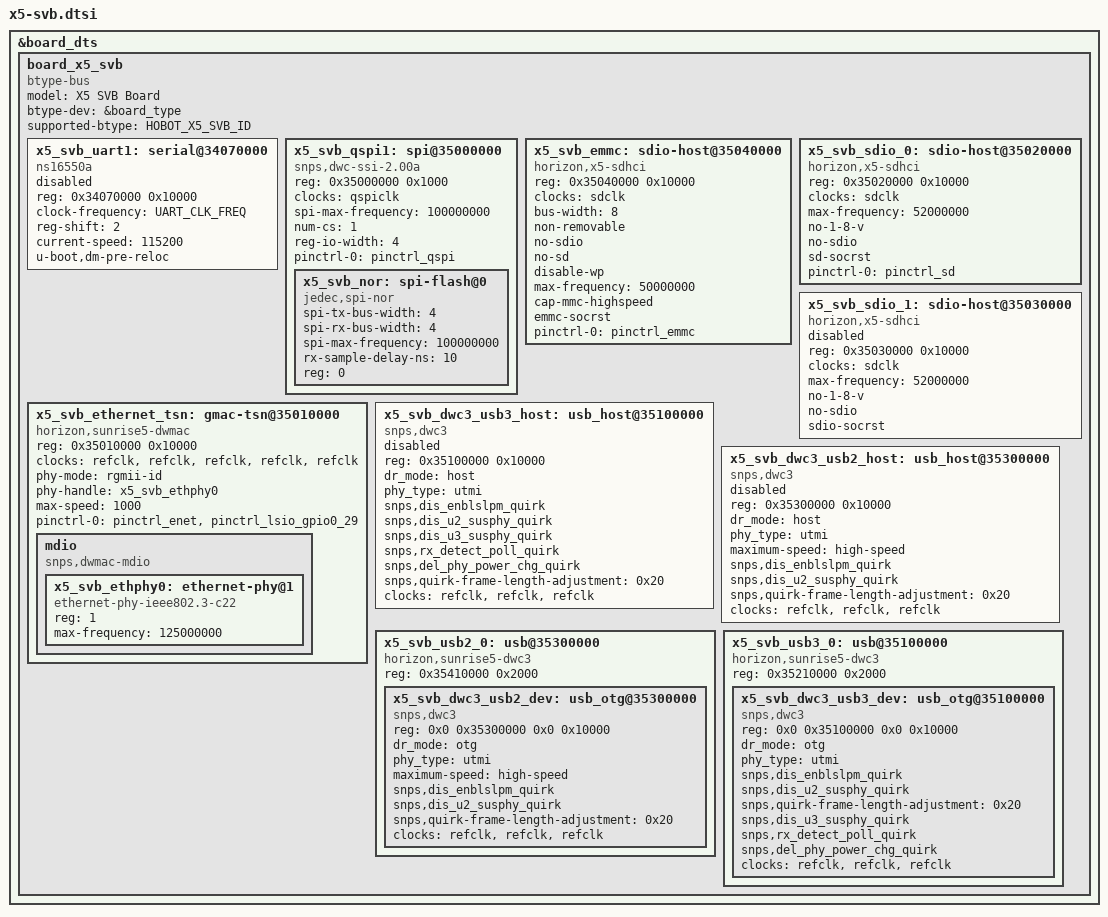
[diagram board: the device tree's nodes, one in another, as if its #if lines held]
#include "pinmux-func.dtsi"

&board_dts {
	board_x5_svb {
		compatible = "btype-bus";
		model = "X5 SVB Board";
		#address-cells = <1>;
		#size-cells = <1>;
		ranges;

		btype-dev = &board_type;
		supported-btype =
			<
			HOBOT_X5_SVB_ID
			>;

		x5_svb_uart1: serial@34070000 {
			compatible = "ns16550a";
			reg = <0x34070000 0x10000>;
			clock-frequency = <UART_CLK_FREQ>;
			reg-shift = <2>;
			current-speed = <115200>;
			u-boot,dm-pre-reloc;
			status = "disabled";
		};

		x5_svb_qspi1: spi@35000000 {
			status = "okay";
			compatible = "snps,dwc-ssi-2.00a";
			reg = <0x35000000 0x1000>;
			clocks = <&qspiclk>;
			spi-max-frequency = <100000000>;
			num-cs = <1>;
			reg-io-width = <4>;
			#address-cells = <1>;
			#size-cells = <0>;
			pinctrl-names = "default";
			pinctrl-0 = <&pinctrl_qspi>;
#ifdef CONFIG_DM_SPI_FLASH
			x5_svb_nor: spi-flash@0 {
				compatible = "jedec,spi-nor";
				spi-tx-bus-width = <4>;
				spi-rx-bus-width = <4>;
				spi-max-frequency = <100000000>;
				rx-sample-delay-ns = <10>;
				reg = <0>;
			};
#else
			x5_svb_nand: spi-flash@0 {
				compatible = "spi-nand";
				spi-tx-bus-width = <4>;
				spi-rx-bus-width = <4>;
				spi-max-frequency = <100000000>;
				rx-sample-delay-ns = <10>;
				reg = <0>;
			};
#endif
		};

		x5_svb_emmc: sdio-host@35040000 {
			compatible = "horizon,x5-sdhci";
			reg = <0x35040000 0x10000>;
			clocks = <&sdclk>;
			bus-width = <8>;
			non-removable;
			no-sdio;
			no-sd;
			disable-wp;
			// dwcmshc,no-cmd-conflict-check;
			// dwcmshc,negative-edge-sample;
			status = "okay";
			max-frequency = <50000000>;
			cap-mmc-highspeed;
			emmc-socrst;
			// mmc-hs200-1_8v;
			pinctrl-names = "default";
			pinctrl-0 = <&pinctrl_emmc>;
		};

		x5_svb_sdio_0: sdio-host@35020000 {
			compatible = "horizon,x5-sdhci";
			reg = <0x35020000 0x10000>;
			clocks = <&sdclk>;
			max-frequency = <52000000>;
			no-1-8-v;
			no-sdio;
			sd-socrst;
			status = "okay";
			pinctrl-names = "default";
			pinctrl-0 = <&pinctrl_sd>;
		};

		x5_svb_sdio_1: sdio-host@35030000 {
			compatible = "horizon,x5-sdhci";
			reg = <0x35030000 0x10000>;
			clocks = <&sdclk>;
			max-frequency = <52000000>;
			no-1-8-v;
			no-sdio;
			sdio-socrst;
			status = "disabled";
		};

		x5_svb_ethernet_tsn: gmac-tsn@35010000 {
			compatible = "horizon,sunrise5-dwmac";
			status = "okay";
			reg = <0x35010000 0x10000>;
			reg-names = "stmmaceth";
			clock-names = "stmmaceth",
					"mac-clk-tx",
					"mac-clk-rx",
					"ethstp",
					"syscfg-clk";
			clocks = <&refclk>,
				<&refclk>,
				<&refclk>,
				<&refclk>,
				<&refclk>;
			phy-mode = "rgmii-id";
			phy-handle = <&x5_svb_ethphy0>;
			max-speed = <1000>;
			pinctrl-names = "default";
			pinctrl-0 = <&pinctrl_enet &pinctrl_lsio_gpio0_29>;

			mdio {
				compatible = "snps,dwmac-mdio";
				#address-cells = <1>;
				#size-cells = <0>;

				x5_svb_ethphy0: ethernet-phy@1 {
					compatible = "ethernet-phy-ieee802.3-c22";
					reg = <1>;
					max-frequency = <125000000>;
				};
			};
		};

		x5_svb_dwc3_usb3_host: usb_host@35100000 {
			compatible = "snps,dwc3";
			status = "disabled";
			reg = <0x35100000 0x10000>;
			dr_mode = "host"; // peripheral/host
			phy_type = "utmi";
			phy-names = "usb3-phy";
			snps,dis_enblslpm_quirk;
			snps,dis_u2_susphy_quirk;
			snps,dis_u3_susphy_quirk;
			snps,rx_detect_poll_quirk;
			snps,del_phy_power_chg_quirk;
			snps,quirk-frame-length-adjustment = <0x20>;
			clocks = <&refclk &refclk &refclk>;
			clock-names = "ref", "bus_early", "suspend";
		};

		x5_svb_dwc3_usb2_host: usb_host@35300000 {
			compatible = "snps,dwc3";
			status = "disabled";
			reg = <0x35300000 0x10000>;
			dr_mode = "host"; // peripheral/host
			phy_type = "utmi";
			phy-names = "usb2-phy";
			maximum-speed = "high-speed";
			snps,dis_enblslpm_quirk;
			snps,dis_u2_susphy_quirk;
			snps,quirk-frame-length-adjustment = <0x20>;
			clocks = <&refclk &refclk &refclk>;
			clock-names = "ref", "bus_early", "suspend";
		};

		x5_svb_usb2_0: usb@35300000 {
			compatible = "horizon,sunrise5-dwc3";
			reg = <0x35410000 0x2000>;
			reg-names = "usb2-csr-base";

			#address-cells = <2>;
			#size-cells = <2>;
			status = "okay";

			x5_svb_dwc3_usb2_dev: usb_otg@35300000 {
				compatible = "snps,dwc3";
				status = "okay";
				reg = <0x0 0x35300000 0x0 0x10000>;
				reg-names = "dwc3-base";
				dr_mode = "otg"; // peripheral/host
				phy_type = "utmi";
				phy-names = "usb2-phy";
				maximum-speed = "high-speed";
				snps,dis_enblslpm_quirk;
				snps,dis_u2_susphy_quirk;
				snps,quirk-frame-length-adjustment = <0x20>;
				clocks = <&refclk &refclk &refclk>;
				clock-names = "ref", "bus_early", "suspend";
			};
		};

		x5_svb_usb3_0: usb@35100000 {
			compatible = "horizon,sunrise5-dwc3";
			reg = <0x35210000 0x2000>;
			reg-names = "usb3-csr-base";

			#address-cells = <2>;
			#size-cells = <2>;
			status = "okay";

			x5_svb_dwc3_usb3_dev: usb_otg@35100000 {
				compatible = "snps,dwc3";
				status = "okay";
				reg = <0x0 0x35100000 0x0 0x10000>;
				dr_mode = "otg"; // peripheral/host
				phy_type = "utmi";
				phy-names = "usb3-phy";
				snps,dis_enblslpm_quirk;
				snps,dis_u2_susphy_quirk;
				snps,quirk-frame-length-adjustment = <0x20>;
				snps,dis_u3_susphy_quirk;
				snps,rx_detect_poll_quirk;
				snps,del_phy_power_chg_quirk;
				clocks = <&refclk &refclk &refclk>;
				clock-names = "ref", "bus_early", "suspend";
			};
		};
	};
};
